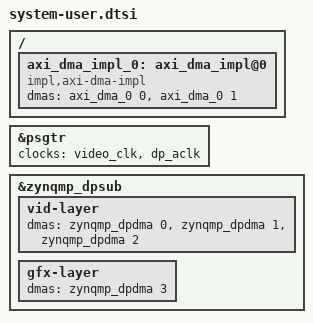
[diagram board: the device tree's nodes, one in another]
/ {
  axi_dma_impl_0: axi_dma_impl@0 {
    compatible = "impl,axi-dma-impl";
    dma-names = "loopback-tx", "loopback-rx";
    dmas      = <&axi_dma_0 0>, <&axi_dma_0 1>;
  };
};

&psgtr {
  clocks = <&video_clk> , <&dp_aclk>;
  clock-names = "ref0", "ref3";
};

&zynqmp_dpsub {
   vid-layer {
       dma-names = "vid0", "vid1", "vid2";
       dmas = <&zynqmp_dpdma 0>,
              <&zynqmp_dpdma 1>,
              <&zynqmp_dpdma 2>;
   };

   gfx-layer {
       dma-names = "gfx0";
       dmas = <&zynqmp_dpdma 3>;
   };
};

